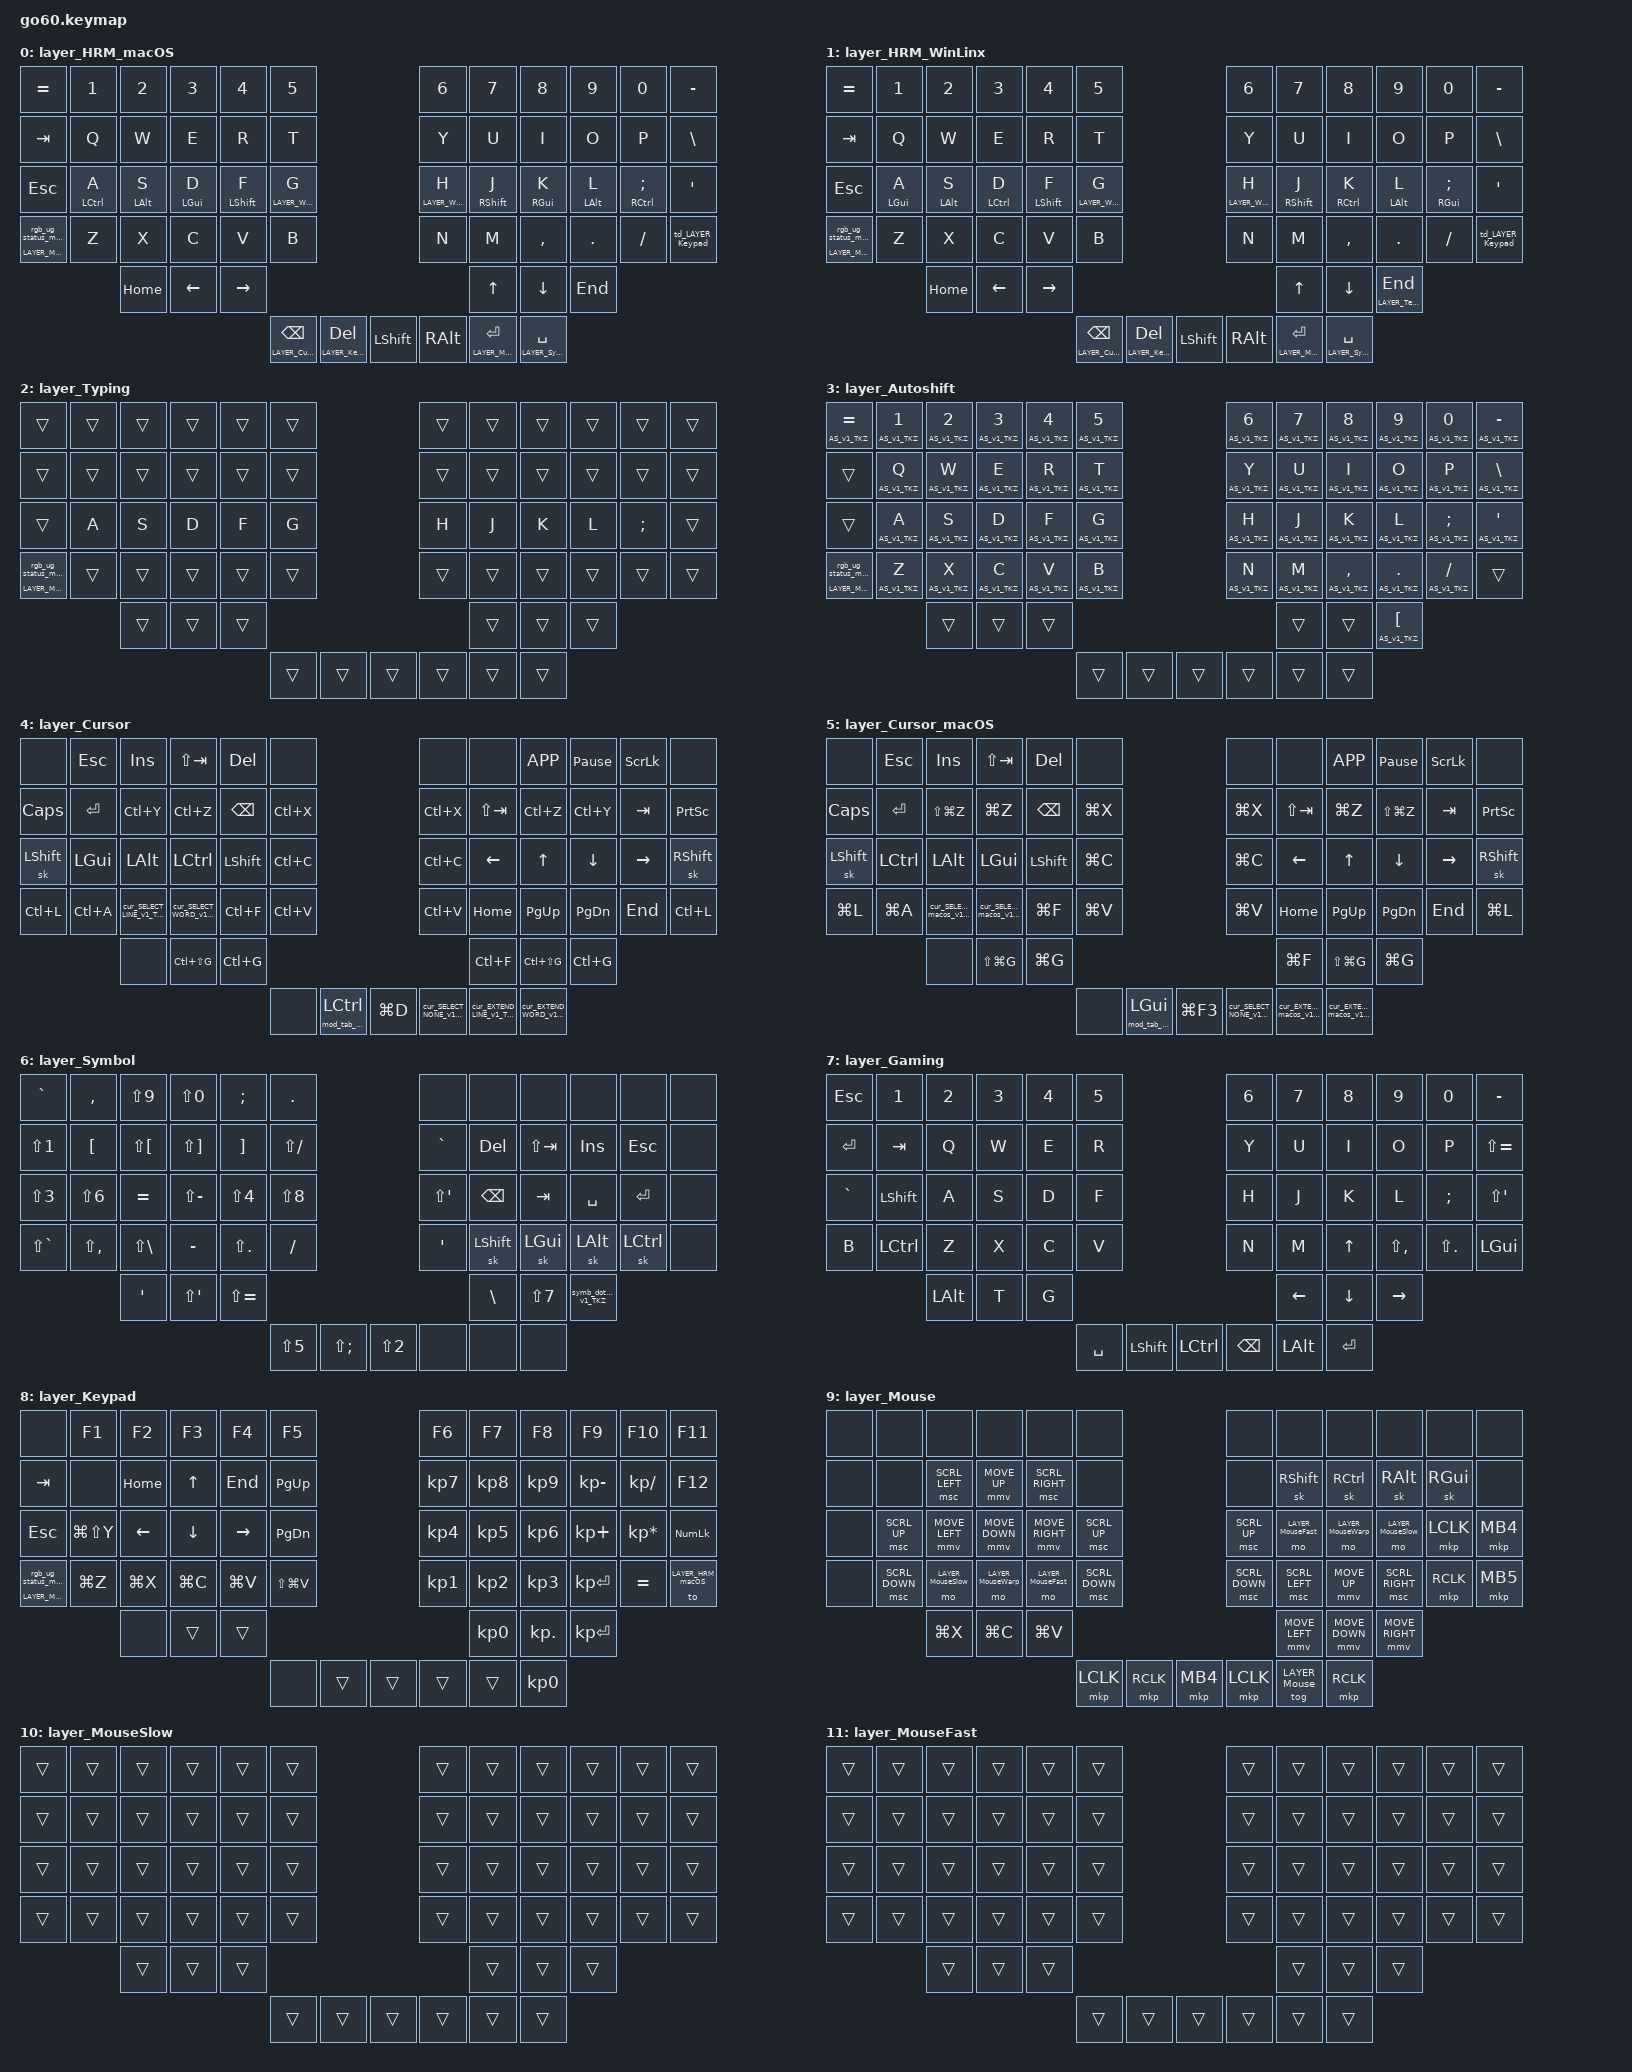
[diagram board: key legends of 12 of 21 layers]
/*
 * Copyright (c) 2020 The ZMK Contributors
 * Copyright (c) 2025 Innaworks Development Limited, trading as MoErgo
 *
 * SPDX-License-Identifier: MIT
 */


/* THIS FILE WAS GENERATED BY GO60 LAYOUT EDITOR
 *
 * This file was generated automatically. You may or may not want to
 * edit it directly.
 */

#include <behaviors.dtsi>

/* Include all behavior includes needed */

#include <dt-bindings/zmk/outputs.h>
#include <dt-bindings/zmk/keys.h>
#include <dt-bindings/zmk/bt.h>
#include <dt-bindings/zmk/rgb.h>

#include <input/processors.dtsi>
#include <dt-bindings/zmk/input_transform.h>
#include <zephyr/dt-bindings/input/input-event-codes.h>

/* On demand includes */
#include <dt-bindings/zmk/input_transform.h>
#include <dt-bindings/zmk/pointing.h>
#include <input/processors.dtsi>

/* Helper Macros, based on https://github.com/urob/zmk-helpers/ */

#pragma once

#define ZMK_HELPER_STRINGIFY(x) #x

// Preprocessor mechanism to overload macros, cf. https://stackoverflow.com/a/27051616/6114651
#define VARGS_(_10, _9, _8, _7, _6, _5, _4, _3, _2, _1, N, ...) N
#define VARGS(...) VARGS_(__VA_ARGS__, 10, 9, 8, 7, 6, 5, 4, 3, 2, 1, 0)
#define CONCAT_(a, b) a##b
#define CONCAT(a, b) CONCAT_(a, b)

#define ZMK_BEHAVIOR_CORE_tap_dance  \
    compatible = "zmk,behavior-tap-dance"; \
    #binding-cells = <0>

#define ZMK_BEHAVIOR(name, type, ...) \
    name: name { \
        ZMK_BEHAVIOR_CORE_ ## type; \
        __VA_ARGS__ \
    };

#define ZMK_TAP_DANCE(name, ...) \
    ZMK_BEHAVIOR(name, tap_dance, __VA_ARGS__)

#define ZMK_TD_LAYER(name, layer) \
    ZMK_TAP_DANCE(name, \
        tapping-term-ms = <200>; \
        bindings = <&mo layer>, <&to layer>; \
)





/* Key positions */

#define POS_LH_C6R1 0
#define POS_LH_C5R1 1
#define POS_LH_C4R1 2
#define POS_LH_C3R1 3
#define POS_LH_C2R1 4
#define POS_LH_C1R1 5
#define POS_RH_C1R1 6
#define POS_RH_C2R1 7
#define POS_RH_C3R1 8
#define POS_RH_C4R1 9
#define POS_RH_C5R1 10
#define POS_RH_C6R1 11
#define POS_LH_C6R2 12
#define POS_LH_C5R2 13
#define POS_LH_C4R2 14
#define POS_LH_C3R2 15
#define POS_LH_C2R2 16
#define POS_LH_C1R2 17
#define POS_RH_C1R2 18
#define POS_RH_C2R2 19
#define POS_RH_C3R2 20
#define POS_RH_C4R2 21
#define POS_RH_C5R2 22
#define POS_RH_C6R2 23
#define POS_LH_C6R3 24
#define POS_LH_C5R3 25
#define POS_LH_C4R3 26
#define POS_LH_C3R3 27
#define POS_LH_C2R3 28
#define POS_LH_C1R3 29
#define POS_RH_C1R3 30
#define POS_RH_C2R3 31
#define POS_RH_C3R3 32
#define POS_RH_C4R3 33
#define POS_RH_C5R3 34
#define POS_RH_C6R3 35
#define POS_LH_C6R4 36
#define POS_LH_C5R4 37
#define POS_LH_C4R4 38
#define POS_LH_C3R4 39
#define POS_LH_C2R4 40
#define POS_LH_C1R4 41
#define POS_RH_C1R4 42
#define POS_RH_C2R4 43
#define POS_RH_C3R4 44
#define POS_RH_C4R4 45
#define POS_RH_C5R4 46
#define POS_RH_C6R4 47
#define POS_LH_C4R5 48
#define POS_LH_C3R5 49
#define POS_LH_C2R5 50
#define POS_RH_C2R5 51
#define POS_RH_C3R5 52
#define POS_RH_C4R5 53
#define POS_LH_T1 54
#define POS_LH_T2 55
#define POS_LH_T3 56
#define POS_RH_T3 57
#define POS_RH_T2 58
#define POS_RH_T1 59


#define LEFT_HAND_KEYS \
  POS_LH_C1R1 POS_LH_C2R1 POS_LH_C3R1 POS_LH_C4R1 POS_LH_C5R1 POS_LH_C6R1 \
  POS_LH_C1R2 POS_LH_C2R2 POS_LH_C3R2 POS_LH_C4R2 POS_LH_C5R2 POS_LH_C6R2 \
  POS_LH_C1R3 POS_LH_C2R3 POS_LH_C3R3 POS_LH_C4R3 POS_LH_C5R3 POS_LH_C6R3 \
  POS_LH_C1R4 POS_LH_C2R4 POS_LH_C3R4 POS_LH_C4R4 POS_LH_C5R4 POS_LH_C6R4 \
              POS_LH_C2R5 POS_LH_C3R5 POS_LH_C4R5

#define RIGHT_HAND_KEYS \
  POS_RH_C1R1 POS_RH_C2R1 POS_RH_C3R1 POS_RH_C4R1 POS_RH_C5R1 POS_RH_C6R1 \
  POS_RH_C1R2 POS_RH_C2R2 POS_RH_C3R2 POS_RH_C4R2 POS_RH_C5R2 POS_RH_C6R2 \
  POS_RH_C1R3 POS_RH_C2R3 POS_RH_C3R3 POS_RH_C4R3 POS_RH_C5R3 POS_RH_C6R3 \
  POS_RH_C1R4 POS_RH_C2R4 POS_RH_C3R4 POS_RH_C4R4 POS_RH_C5R4 POS_RH_C6R4 \
              POS_RH_C2R5 POS_RH_C3R5 POS_RH_C4R5

#define THUMB_KEYS \
  POS_LH_T1 POS_LH_T2 POS_LH_T3 \
  POS_RH_T1 POS_RH_T2 POS_RH_T3

/* Environment and metadata defines */
#define KB_TYPE_GLOVE_80 1
#define KB_TYPE_GO_60    2

#define KB_TYPE          KB_TYPE_GO_60
#define EDITOR_HOST_OS   'M'

/* Automatically generated layer name defines */
#define LAYER_HRM_macOS 0
#define LAYER_HRM_WinLinx 1
#define LAYER_Typing 2
#define LAYER_Autoshift 3
#define LAYER_Cursor 4
#define LAYER_Cursor_macOS 5
#define LAYER_Symbol 6
#define LAYER_Gaming 7
#define LAYER_Keypad 8
#define LAYER_Mouse 9
#define LAYER_MouseSlow 10
#define LAYER_MouseFast 11
#define LAYER_MouseWarp 12
#define LAYER_Magic 13
#define LAYER_WM_practice 14
#define LAYER_WM_Win 15
#define LAYER_VSCode_macOS 16
#define LAYER_VSCode_Win 17
#define LAYER_Teams 18
/* Windows-only overlays; never entered by a key — see the conditional_layers node. */
#define LAYER_Keypad_Win 19
#define LAYER_Mouse_Win 20

/* To deal with the situation where there is no Lower layer, to keep &lower happy */
#ifndef LAYER_Lower
#define LAYER_Lower 0
#endif

/* Generated input processors */


/* Custom Device-tree */


/* Input Listeners */
&mmv_input_listener {
    // base pointer speed (tools/edits/mouse-speed.js)
    LAYER_Mouse {
        layers = <LAYER_Mouse>;
        input-processors = <&zip_xy_scaler 2 1>;
    };
    // LAYER_MouseSlow
    LAYER_MouseSlow {
        layers = <LAYER_MouseSlow>;
        input-processors = <&zip_xy_scaler 1 18>;
    };
    // LAYER_MouseFast
    LAYER_MouseFast {
        layers = <LAYER_MouseFast>;
        input-processors = <&zip_xy_scaler 3 2>;
    };
    // LAYER_MouseFast
    LAYER_MouseWarp {
        layers = <LAYER_MouseWarp>;
        input-processors = <&zip_xy_scaler 6 1>;
    };
};

&msc_input_listener {
    // base scroll rate (tools/edits/mouse-speed.js)
    LAYER_Mouse {
        layers = <LAYER_Mouse>;
        input-processors = <&zip_scroll_scaler 1 3>;
    };
    // LAYER_MouseSlow
    LAYER_MouseSlow {
        layers = <LAYER_MouseSlow>;
        input-processors = <&zip_scroll_scaler 1 9>;
    };
    // LAYER_MouseFast
    LAYER_MouseFast {
        layers = <LAYER_MouseFast>;
        input-processors = <&zip_scroll_scaler 3 1>;
    };
    // LAYER_MouseWarp
    LAYER_MouseWarp {
        layers = <LAYER_MouseWarp>;
        input-processors = <&zip_scroll_scaler 12 1>;
    };
};

&cirque_lh_listener {
    // Left pad = scroll wheel. Gains are ABSOLUTE: a speed hold's override
    // replaces these base processors rather than stacking on them (ZMK
    // input-listener semantics, no `process-next`), so each tier is spelled
    // out in full. Base is MoErgo's stock 1/8; raw deltas (the old base) were
    // 8x that and unusable. Same direction on every tier.
    input-processors = <&zip_xy_scaler 1 8>, <&zip_xy_to_scroll_mapper>, <&zip_temp_layer LAYER_Mouse 250>;
    layer_MouseSlow {
        layers = <LAYER_MouseSlow>;
        input-processors = <&zip_xy_scaler 1 16>, <&zip_xy_to_scroll_mapper>;
    };
    layer_MouseFast {
        layers = <LAYER_MouseFast>;
        input-processors = <&zip_xy_scaler 1 4>, <&zip_xy_to_scroll_mapper>;
    };
    layer_MouseWarp {
        layers = <LAYER_MouseWarp>;
        input-processors = <&zip_xy_scaler 1 2>, <&zip_xy_to_scroll_mapper>;
    };
};

&cirque_rh_listener {
    // Right pad = pointer. Absolute gains, same replace-not-stack rule as the
    // left pad. Base is MoErgo's stock 3x (raw 1x was unusably slow); Warp is
    // stock's own fast tier, Slow keeps raw 1x for pixel work.
    input-processors = <&zip_xy_scaler 3 1>, <&zip_temp_layer LAYER_Mouse 250>;
    layer_MouseSlow {
        layers = <LAYER_MouseSlow>;
        input-processors = <&zip_xy_scaler 1 1>;
    };
    layer_MouseFast {
        layers = <LAYER_MouseFast>;
        input-processors = <&zip_xy_scaler 6 1>;
    };
    layer_MouseWarp {
        layers = <LAYER_MouseWarp>;
        input-processors = <&zip_xy_scaler 9 1>;
    };
};

/* System behavior and macros */
/ {
    behaviors {
        ZMK_TD_LAYER(lower, LAYER_Lower)
    };
};

/ {
    macros {
        rgb_ug_status_macro: rgb_ug_status_macro {
            label = "RGB_UG_STATUS";
            compatible = "zmk,behavior-macro";
            #binding-cells = <0>;
            bindings
                = <&rgb_ug RGB_STATUS>;
        };
    };
};

/ {
#ifdef BT_DISC_CMD
    behaviors {
        bt_0: bt_0 {
            compatible = "zmk,behavior-tap-dance";
            label = "BT_0";
            #binding-cells = <0>;
            tapping-term-ms = <200>;
            bindings = <&bt_select_0>, <&bt BT_DISC 0>;
        };
        bt_1: bt_1 {
            compatible = "zmk,behavior-tap-dance";
            label = "BT_1";
            #binding-cells = <0>;
            tapping-term-ms = <200>;
            bindings = <&bt_select_1>, <&bt BT_DISC 1>;
        };
        bt_2: bt_2 {
            compatible = "zmk,behavior-tap-dance";
            label = "BT_2";
            #binding-cells = <0>;
            tapping-term-ms = <200>;
            bindings = <&bt_select_2>, <&bt BT_DISC 2>;
        };
        bt_3: bt_3 {
            compatible = "zmk,behavior-tap-dance";
            label = "BT_3";
            #binding-cells = <0>;
            tapping-term-ms = <200>;
            bindings = <&bt_select_3>, <&bt BT_DISC 3>;
        };
    };
    macros {
        bt_select_0: bt_select_0 {
            label = "BT_SELECT_0";
            compatible = "zmk,behavior-macro";
            #binding-cells = <0>;
            bindings
                = <&out OUT_BLE>,
                  <&bt BT_SEL 0>;
        };
        bt_select_1: bt_select_1 {
            label = "BT_SELECT_1";
            compatible = "zmk,behavior-macro";
            #binding-cells = <0>;
            bindings
                = <&out OUT_BLE>,
                  <&bt BT_SEL 1>;
        };
        bt_select_2: bt_select_2 {
            label = "BT_SELECT_2";
            compatible = "zmk,behavior-macro";
            #binding-cells = <0>;
            bindings
                = <&out OUT_BLE>,
                  <&bt BT_SEL 2>;
        };
        bt_select_3: bt_select_3 {
            label = "BT_SELECT_3";
            compatible = "zmk,behavior-macro";
            #binding-cells = <0>;
            bindings
                = <&out OUT_BLE>,
                  <&bt BT_SEL 3>;
        };
    };
#else
    macros {
        bt_0: bt_0 {
            label = "BT_0";
            compatible = "zmk,behavior-macro";
            #binding-cells = <0>;
            bindings
                = <&out OUT_BLE>,
                  <&bt BT_SEL 0>;
        };
        bt_1: bt_1 {
            label = "BT_1";
            compatible = "zmk,behavior-macro";
            #binding-cells = <0>;
            bindings
                = <&out OUT_BLE>,
                  <&bt BT_SEL 1>;
        };
        bt_2: bt_2 {
            label = "BT_2";
            compatible = "zmk,behavior-macro";
            #binding-cells = <0>;
            bindings
                = <&out OUT_BLE>,
                  <&bt BT_SEL 2>;
        };
        bt_3: bt_3 {
            label = "BT_3";
            compatible = "zmk,behavior-macro";
            #binding-cells = <0>;
            bindings
                = <&out OUT_BLE>,
                  <&bt BT_SEL 3>;
        };
    };
#endif
};

/ {
    behaviors {
        magic: magic {
            compatible = "zmk,behavior-hold-tap";
            label = "MAGIC_HOLD_TAP";
            #binding-cells = <2>;
            flavor = "tap-preferred";
            tapping-term-ms = <200>;
            bindings = <&mo>, <&rgb_ug_status_macro>;
        };
    };
};


/* Custom Defined Behaviors */
/ {

};

/* Automatically generated macro definitions */
/ {
    macros {

        // AutoShift Helper- &AS main macro is chained to &AS_HT hold tap and &AS_Shifted macro - TailorKey
        AS_Shifted_v1_TKZ: AS_Shifted_v1_TKZ {
            label = "&AS_SHIFTED_V1_TKZ";
            compatible = "zmk,behavior-macro-one-param";
            #binding-cells = <1>;
            tap-ms = <0>;
            wait-ms = <0>;
            bindings = <&macro_press>
                , <&kp LSHFT>
                , <&macro_tap>
                , <&macro_param_1to1>
                , <&kp MACRO_PLACEHOLDER>
                , <&macro_release>
                , <&kp LSHFT>;
        };

        // AutoShift (Assign &AS to a Key) - &AS main macro is chained to &AS_HT hold tap and &AS_Shifted macro - TailorKey
        AS_v1_TKZ: AS_v1_TKZ {
            label = "&AS_V1_TKZ";
            compatible = "zmk,behavior-macro-one-param";
            #binding-cells = <1>;
            tap-ms = <0>;
            wait-ms = <0>;
            bindings = <&macro_press>
                , <&macro_param_1to1>
                , <&macro_param_1to2>
                , <&AS_HT_v2_TKZ MACRO_PLACEHOLDER MACRO_PLACEHOLDER>
                , <&macro_pause_for_release>
                , <&macro_release>
                , <&macro_param_1to1>
                , <&macro_param_1to2>
                , <&AS_HT_v2_TKZ MACRO_PLACEHOLDER MACRO_PLACEHOLDER>;
        };

        // Cursor Layer - Extent Line (seq) - TailorKey
        cur_EXTEND_LINE_macos_v1_TKZ: cur_EXTEND_LINE_macos_v1_TKZ {
            label = "&CUR_EXTEND_LINE_MACOS_V1_TKZ";
            compatible = "zmk,behavior-macro";
            #binding-cells = <0>;
            tap-ms = <1>;
            wait-ms = <1>;
            bindings = <&kp LG(LS(RIGHT))>;
        };

        // Cursor Layer - Extent Line (seq) - TailorKey
        cur_EXTEND_LINE_v1_TKZ: cur_EXTEND_LINE_v1_TKZ {
            label = "&CUR_EXTEND_LINE_V1_TKZ";
            compatible = "zmk,behavior-macro";
            #binding-cells = <0>;
            tap-ms = <1>;
            wait-ms = <1>;
            bindings = <&kp LS(END)>;
        };

        // Cursor Layer - Extend Word (seq) - TailorKey
        cur_EXTEND_WORD_macos_v1_TKZ: cur_EXTEND_WORD_macos_v1_TKZ {
            label = "&CUR_EXTEND_WORD_MACOS_V1_TKZ";
            compatible = "zmk,behavior-macro";
            #binding-cells = <0>;
            tap-ms = <1>;
            wait-ms = <1>;
            bindings = <&kp LA(LS(RIGHT))>;
        };

        // Cursor Layer - Extend Word (seq) - TailorKey
        cur_EXTEND_WORD_v1_TKZ: cur_EXTEND_WORD_v1_TKZ {
            label = "&CUR_EXTEND_WORD_V1_TKZ";
            compatible = "zmk,behavior-macro";
            #binding-cells = <0>;
            tap-ms = <1>;
            wait-ms = <1>;
            bindings = <&kp LC(LS(RIGHT))>;
        };

        // Cursor Layer macos - Select Line (seq) - TailorKey
        cur_SELECT_LINE_macos_v1_TKZ: cur_SELECT_LINE_macos_v1_TKZ {
            label = "&CUR_SELECT_LINE_MACOS_V1_TKZ";
            compatible = "zmk,behavior-macro";
            #binding-cells = <0>;
            tap-ms = <1>;
            wait-ms = <1>;
            bindings = <&kp LG(LEFT)>
                , <&kp LG(LS(RIGHT))>;
        };

        // Cursor Layer - Select Line (seq) - TailorKey
        cur_SELECT_LINE_v1_TKZ: cur_SELECT_LINE_v1_TKZ {
            label = "&CUR_SELECT_LINE_V1_TKZ";
            compatible = "zmk,behavior-macro";
            #binding-cells = <0>;
            tap-ms = <1>;
            wait-ms = <1>;
            bindings = <&kp HOME>
                , <&kp LS(END)>;
        };

        // Cursor Layer - Select None (seq) - TailorKey
        cur_SELECT_NONE_v1_TKZ: cur_SELECT_NONE_v1_TKZ {
            label = "&CUR_SELECT_NONE_V1_TKZ";
            compatible = "zmk,behavior-macro";
            #binding-cells = <0>;
            tap-ms = <1>;
            wait-ms = <1>;
            bindings = <&kp DOWN>
                , <&kp UP>
                , <&kp RIGHT>
                , <&kp LEFT>;
        };

        // Cursor Layer - Select Word (seq) - TailorKey
        cur_SELECT_WORD_macos_v1_TKZ: cur_SELECT_WORD_macos_v1_TKZ {
            label = "&CUR_SELECT_WORD_MACOS_V1_TKZ";
            compatible = "zmk,behavior-macro";
            #binding-cells = <0>;
            tap-ms = <1>;
            wait-ms = <1>;
            bindings = <&kp LA(LEFT)>
                , <&kp LA(LS(RIGHT))>;
        };

        // Cursor Layer - Select Word (seq) - TailorKey
        cur_SELECT_WORD_v1_TKZ: cur_SELECT_WORD_v1_TKZ {
            label = "&CUR_SELECT_WORD_V1_TKZ";
            compatible = "zmk,behavior-macro";
            #binding-cells = <0>;
            tap-ms = <1>;
            wait-ms = <1>;
            bindings = <&kp LC(LEFT)>
                , <&kp LC(LS(RIGHT))>;
        };

        // mod_tab_switcher_chord -  TailorKey
        mod_tab_chord_v2_TKZ: mod_tab_chord_v2_TKZ {
            label = "&MOD_TAB_CHORD_V2_TKZ";
            compatible = "zmk,behavior-macro-two-param";
            #binding-cells = <2>;
            tap-ms = <0>;
            wait-ms = <0>;
            bindings = <&macro_press>
                , <&macro_param_2to1>
                , <&mo MACRO_PLACEHOLDER>
                , <&macro_press>
                , <&macro_param_1to1>
                , <&mod_tab_v2_TKZ MACRO_PLACEHOLDER>
                , <&macro_pause_for_release>
                , <&macro_release>
                , <&macro_param_1to1>
                , <&mod_tab_v2_TKZ MACRO_PLACEHOLDER>
                , <&macro_release>
                , <&macro_param_2to1>
                , <&mo MACRO_PLACEHOLDER>;
        };

        // mod_tab_switcher - TailorKey
        //
        //
        mod_tab_v2_TKZ: mod_tab_v2_TKZ {
            label = "&MOD_TAB_V2_TKZ";
            compatible = "zmk,behavior-macro-one-param";
            #binding-cells = <1>;
            tap-ms = <0>;
            wait-ms = <0>;
            bindings = <&macro_press>
                , <&macro_param_1to1>
                , <&kp MACRO_PLACEHOLDER>
                , <&macro_tap>
                , <&kp TAB>
                , <&macro_pause_for_release>
                , <&macro_release>
                , <&macro_param_1to1>
                , <&kp MACRO_PLACEHOLDER>;
        };

        // macro string1 sample - Magic Layer F1 - Text output sample macro 1 "¡Hola!" - TailorKey
        mstr1_v1_TKZ: mstr1_v1_TKZ {
            label = "&MSTR1_V1_TKZ";
            compatible = "zmk,behavior-macro";
            #binding-cells = <0>;
            bindings = <&macro_press>
                , <&kp RALT>
                , <&macro_tap>
                , <&kp KP_N0>
                , <&kp KP_N1>
                , <&kp KP_N6>
                , <&kp KP_N1>
                , <&macro_release>
                , <&kp RALT>
                , <&macro_press>
                , <&kp LSHFT>
                , <&macro_tap>
                , <&kp H>
                , <&macro_release>
                , <&kp LSHFT>
                , <&macro_tap>
                , <&kp O>
                , <&kp L>
                , <&kp A>
                , <&kp LS(N1)>
                , <&kp SPACE>
                , <&kp RET>;
        };

        // Symbol layer dot dot
        symb_dotdot_v1_TKZ: symb_dotdot_v1_TKZ {
            label = "&SYMB_DOTDOT_V1_TKZ";
            compatible = "zmk,behavior-macro";
            #binding-cells = <0>;
            tap-ms = <0>;
            wait-ms = <0>;
            bindings = <&macro_tap>
                , <&kp DOT>
                , <&kp DOT>;
        };

        // BT profile 0 = the Mac. Taps Ctrl+Shift+F17 so the machine being left pushes the MX Master to the same host, hops, then lands the base layer on macOS
        bt_hop_0: bt_hop_0 {
            label = "&BT_HOP_0";
            compatible = "zmk,behavior-macro";
            #binding-cells = <0>;
            tap-ms = <30>;
            wait-ms = <125>;
            bindings = <&kp LC(LS(F17))>
                , <&out OUT_BLE>
                , <&bt BT_SEL 0>
                , <&to LAYER_HRM_macOS>;
        };

        // BT profile 1 = the work laptop. Taps Ctrl+Shift+F18 so the machine being left pushes the MX Master to the same host, hops, then lands the base layer on Windows
        bt_hop_1: bt_hop_1 {
            label = "&BT_HOP_1";
            compatible = "zmk,behavior-macro";
            #binding-cells = <0>;
            tap-ms = <30>;
            wait-ms = <125>;
            bindings = <&kp LC(LS(F18))>
                , <&out OUT_BLE>
                , <&bt BT_SEL 1>
                , <&to LAYER_HRM_WinLinx>;
        };

        // BT profile 2 = the personal Windows desktop. Taps Ctrl+Shift+F19 so the machine being left pushes the MX Master to the same host, hops, then lands the base layer on Windows
        bt_hop_2: bt_hop_2 {
            label = "&BT_HOP_2";
            compatible = "zmk,behavior-macro";
            #binding-cells = <0>;
            tap-ms = <30>;
            wait-ms = <125>;
            bindings = <&kp LC(LS(F19))>
                , <&out OUT_BLE>
                , <&bt BT_SEL 2>
                , <&to LAYER_HRM_WinLinx>;
        };

        // BT profile 3 — spare. No machine claims Ctrl+Shift+F20 and no base layer follows it; the hop is all this one does
        bt_hop_3: bt_hop_3 {
            label = "&BT_HOP_3";
            compatible = "zmk,behavior-macro";
            #binding-cells = <0>;
            tap-ms = <30>;
            wait-ms = <125>;
            bindings = <&kp LC(LS(F20))>
                , <&out OUT_BLE>
                , <&bt BT_SEL 3>;
        };
    };
};

/* Automatically generated behavior definitions */
/ {
    behaviors {

        // Layer tap dance behaviors

        ZMK_TD_LAYER(td_LAYER_Keypad, 8)

        // AutoShift Helper - &AS main macro is chained to &AS_HT hold tap and &AS_Shifted macro. For faster typists, it is recommended to decrease the tapping-term-ms value. A suggested value is 135 ms.
        // More: https://github.com/nickcoutsos/keymap-editor/wiki/Autoshift-using-ZMK-behaviors
        AS_HT_v2_TKZ: AS_HT_v2_TKZ {
            compatible = "zmk,behavior-hold-tap";
            #binding-cells = <2>;
            tapping-term-ms = <190>;
            bindings = <&AS_Shifted_v1_TKZ>, <&kp>;
            flavor = "tap-preferred";
        };

        // Homerow Mod for the left index finger - TailorKey.
        // For advanced tuning of HRM values, see: https://docs.google.com/spreadsheets/d/1ESgObQelyz4lnKlfwLYsmofLJulOMK5RdGBsopLe2o8
        HRM_left_index_v1_TKZ: HRM_left_index_v1_TKZ {
            compatible = "zmk,behavior-hold-tap";
            #binding-cells = <2>;
            tapping-term-ms = <190>;
            bindings = <&kp>, <&kp>;
            flavor = "tap-preferred";
            quick-tap-ms = <300>;
            require-prior-idle-ms = <150>;
            hold-trigger-key-positions = <POS_RH_T3 POS_RH_T2 POS_RH_T1 POS_RH_C1R1 POS_RH_C2R1 POS_RH_C3R1 POS_RH_C4R1 POS_RH_C5R1 POS_RH_C1R2 POS_RH_C2R2 POS_RH_C3R2 POS_RH_C4R2 POS_RH_C5R2 POS_RH_C1R3 POS_RH_C2R3 POS_RH_C3R3 POS_RH_C4R3 POS_RH_C5R3 POS_RH_C1R4 POS_RH_C2R4 POS_RH_C3R4 POS_RH_C4R4 POS_RH_C5R4 POS_RH_C2R5 POS_RH_C3R5 POS_RH_C4R5 POS_RH_C6R1 POS_RH_C6R2 POS_RH_C6R3 POS_RH_C6R4 POS_LH_T2 POS_LH_T3 POS_LH_T1>;
            hold-trigger-on-release;
        };

        // Homerow Mod for the left middle finger - TailorKey
        HRM_left_middy_v1_TKZ: HRM_left_middy_v1_TKZ {
            compatible = "zmk,behavior-hold-tap";
            #binding-cells = <2>;
            tapping-term-ms = <210>;
            bindings = <&kp>, <&kp>;
            flavor = "tap-preferred";
            quick-tap-ms = <300>;
            require-prior-idle-ms = <150>;
            hold-trigger-key-positions = <POS_RH_T3 POS_RH_T2 POS_RH_T1 POS_RH_C1R1 POS_RH_C2R1 POS_RH_C3R1 POS_RH_C4R1 POS_RH_C5R1 POS_RH_C1R2 POS_RH_C2R2 POS_RH_C3R2 POS_RH_C4R2 POS_RH_C5R2 POS_RH_C1R3 POS_RH_C2R3 POS_RH_C3R3 POS_RH_C4R3 POS_RH_C5R3 POS_RH_C1R4 POS_RH_C2R4 POS_RH_C3R4 POS_RH_C4R4 POS_RH_C5R4 POS_RH_C2R5 POS_RH_C3R5 POS_RH_C4R5 POS_RH_C6R1 POS_RH_C6R2 POS_RH_C6R3 POS_RH_C6R4 POS_LH_T1 POS_LH_T2 POS_LH_T3>;
            hold-trigger-on-release;
        };

        // Homerow Mod for the left pinky - TailorKey
        HRM_left_pinky_v1_TKZ: HRM_left_pinky_v1_TKZ {
            compatible = "zmk,behavior-hold-tap";
            #binding-cells = <2>;
            tapping-term-ms = <280>;
            bindings = <&kp>, <&kp>;
            flavor = "tap-preferred";
            quick-tap-ms = <300>;
            require-prior-idle-ms = <150>;
            hold-trigger-key-positions = <POS_RH_T3 POS_RH_T2 POS_RH_T1 POS_RH_C1R1 POS_RH_C2R1 POS_RH_C3R1 POS_RH_C4R1 POS_RH_C5R1 POS_RH_C6R1 POS_RH_C2R2 POS_RH_C3R2 POS_RH_C4R2 POS_RH_C5R2 POS_RH_C6R2 POS_RH_C3R3 POS_RH_C4R3 POS_RH_C5R3 POS_RH_C6R3 POS_RH_C3R4 POS_RH_C4R4 POS_RH_C5R4 POS_RH_C6R4 POS_RH_C1R2 POS_RH_C1R3 POS_RH_C2R3 POS_RH_C1R4 POS_RH_C2R4 POS_RH_C2R5 POS_RH_C3R5 POS_RH_C4R5 POS_LH_T1 POS_LH_T2 POS_LH_T3>;
            hold-trigger-on-release;
        };

        // Homerow Mod for the left ring finger 1 - TailorKey
        HRM_left_ring_v1_TKZ: HRM_left_ring_v1_TKZ {
            compatible = "zmk,behavior-hold-tap";
            #binding-cells = <2>;
            tapping-term-ms = <240>;
            bindings = <&kp>, <&kp>;
            flavor = "tap-preferred";
            quick-tap-ms = <300>;
            require-prior-idle-ms = <150>;
            hold-trigger-key-positions = <POS_RH_T3 POS_RH_T2 POS_RH_T1 POS_RH_C1R1 POS_RH_C2R1 POS_RH_C3R1 POS_RH_C4R1 POS_RH_C5R1 POS_RH_C1R2 POS_RH_C2R2 POS_RH_C3R2 POS_RH_C4R2 POS_RH_C5R2 POS_RH_C1R3 POS_RH_C2R3 POS_RH_C3R3 POS_RH_C4R3 POS_RH_C5R3 POS_RH_C1R4 POS_RH_C2R4 POS_RH_C3R4 POS_RH_C4R4 POS_RH_C5R4 POS_RH_C2R5 POS_RH_C3R5 POS_RH_C4R5 POS_RH_C6R1 POS_RH_C6R2 POS_RH_C6R3 POS_RH_C6R4 POS_LH_T1 POS_LH_T2 POS_LH_T3>;
            hold-trigger-on-release;
        };

        // Homerow Mod for the right index finger - TailorKey
        HRM_right_index_v1_TKZ: HRM_right_index_v1_TKZ {
            compatible = "zmk,behavior-hold-tap";
            #binding-cells = <2>;
            tapping-term-ms = <190>;
            bindings = <&kp>, <&kp>;
            flavor = "tap-preferred";
            quick-tap-ms = <300>;
            require-prior-idle-ms = <150>;
            hold-trigger-key-positions = <POS_LH_T3 POS_LH_T2 POS_LH_T1 POS_LH_C6R1 POS_LH_C5R1 POS_LH_C4R1 POS_LH_C3R1 POS_LH_C2R1 POS_LH_C6R2 POS_LH_C5R2 POS_LH_C4R2 POS_LH_C3R2 POS_LH_C2R2 POS_LH_C1R2 POS_LH_C6R3 POS_LH_C5R3 POS_LH_C4R3 POS_LH_C3R3 POS_LH_C2R3 POS_LH_C1R3 POS_LH_C6R4 POS_LH_C5R4 POS_LH_C4R4 POS_LH_C3R4 POS_LH_C2R4 POS_LH_C1R4 POS_LH_C4R5 POS_LH_C3R5 POS_LH_C2R5 POS_LH_C1R1 POS_RH_T3 POS_RH_T2 POS_RH_T1>;
            hold-trigger-on-release;
        };

        // Homerow Mod for the right middle finger - TailorKey
        HRM_right_middy_v1_TKZ: HRM_right_middy_v1_TKZ {
            compatible = "zmk,behavior-hold-tap";
            #binding-cells = <2>;
            tapping-term-ms = <210>;
            bindings = <&kp>, <&kp>;
            flavor = "tap-preferred";
            quick-tap-ms = <300>;
            require-prior-idle-ms = <150>;
            hold-trigger-key-positions = <POS_LH_T3 POS_LH_T2 POS_LH_T1 POS_LH_C6R1 POS_LH_C5R1 POS_LH_C4R1 POS_LH_C3R1 POS_LH_C2R1 POS_LH_C6R2 POS_LH_C5R2 POS_LH_C4R2 POS_LH_C3R2 POS_LH_C2R2 POS_LH_C1R2 POS_LH_C6R3 POS_LH_C5R3 POS_LH_C4R3 POS_LH_C3R3 POS_LH_C2R3 POS_LH_C1R3 POS_LH_C6R4 POS_LH_C5R4 POS_LH_C4R4 POS_LH_C3R4 POS_LH_C2R4 POS_LH_C1R4 POS_LH_C4R5 POS_LH_C3R5 POS_LH_C2R5 POS_LH_C1R1 POS_RH_T3 POS_RH_T2 POS_RH_T1>;
            hold-trigger-on-release;
        };

        // Homerow Mod for the right pinky - TailorKey
        HRM_right_pinky_v1_TKZ: HRM_right_pinky_v1_TKZ {
            compatible = "zmk,behavior-hold-tap";
            #binding-cells = <2>;
            tapping-term-ms = <280>;
            bindings = <&kp>, <&kp>;
            flavor = "tap-preferred";
            quick-tap-ms = <300>;
            require-prior-idle-ms = <150>;
            hold-trigger-key-positions = <POS_LH_T3 POS_LH_T2 POS_LH_T1 POS_LH_C6R1 POS_LH_C5R1 POS_LH_C4R1 POS_LH_C3R1 POS_LH_C2R1 POS_LH_C6R2 POS_LH_C5R2 POS_LH_C4R2 POS_LH_C3R2 POS_LH_C2R2 POS_LH_C1R2 POS_LH_C6R3 POS_LH_C5R3 POS_LH_C4R3 POS_LH_C3R3 POS_LH_C2R3 POS_LH_C1R3 POS_LH_C6R4 POS_LH_C5R4 POS_LH_C4R4 POS_LH_C3R4 POS_LH_C2R4 POS_LH_C1R4 POS_LH_C4R5 POS_LH_C3R5 POS_LH_C2R5 POS_LH_C1R1 POS_RH_T3 POS_RH_T2 POS_RH_T1>;
            hold-trigger-on-release;
        };

        // Homerow Mod for the right ring 1 - TailorKey
        //
        HRM_right_ring_v1_TKZ: HRM_right_ring_v1_TKZ {
            compatible = "zmk,behavior-hold-tap";
            #binding-cells = <2>;
            tapping-term-ms = <240>;
            bindings = <&kp>, <&kp>;
            flavor = "tap-preferred";
            quick-tap-ms = <300>;
            require-prior-idle-ms = <150>;
            hold-trigger-key-positions = <POS_LH_T3 POS_LH_T2 POS_LH_T1 POS_LH_C6R1 POS_LH_C5R1 POS_LH_C4R1 POS_LH_C3R1 POS_LH_C2R1 POS_LH_C6R2 POS_LH_C5R2 POS_LH_C4R2 POS_LH_C3R2 POS_LH_C2R2 POS_LH_C1R2 POS_LH_C6R3 POS_LH_C5R3 POS_LH_C4R3 POS_LH_C3R3 POS_LH_C2R3 POS_LH_C1R3 POS_LH_C6R4 POS_LH_C5R4 POS_LH_C4R4 POS_LH_C3R4 POS_LH_C2R4 POS_LH_C1R4 POS_LH_C4R5 POS_LH_C3R5 POS_LH_C2R5 POS_LH_C1R1 POS_RH_T3 POS_RH_T2 POS_RH_T1>;
            hold-trigger-on-release;
        };

        // space_layer_access - TailorKey
        space_v3_TKZ: space_v3_TKZ {
            compatible = "zmk,behavior-hold-tap";
            #binding-cells = <2>;
            tapping-term-ms = <250>;
            bindings = <&mo>, <&kp>;
            flavor = "tap-preferred";
            quick-tap-ms = <150>;
            require-prior-idle-ms = <200>;
        };

        // thumb_layer_access - TailorKey
        thumb_v2_TKZ: thumb_v2_TKZ {
            compatible = "zmk,behavior-hold-tap";
            #binding-cells = <2>;
            tapping-term-ms = <250>;
            bindings = <&mo>, <&kp>;
            flavor = "tap-preferred";
            quick-tap-ms = <300>;
            require-prior-idle-ms = <150>;
        };

        // WM practice layer entry on G. Positional: only the WM keys can trigger the hold, so ordinary words containing g resolve as a tap.
        WM_hold_v1: WM_hold_v1 {
            compatible = "zmk,behavior-hold-tap";
            #binding-cells = <2>;
            tapping-term-ms = <250>;
            bindings = <&mo>, <&kp>;
            flavor = "tap-preferred";
            quick-tap-ms = <300>;
            require-prior-idle-ms = <150>;
            hold-trigger-key-positions = <POS_RH_C2R2 POS_RH_C3R2 POS_RH_C4R2 POS_RH_C5R2 POS_RH_C2R3 POS_RH_C3R3 POS_RH_C4R3 POS_RH_C5R3 POS_RH_C2R4 POS_RH_C3R4 POS_RH_C4R4 POS_RH_C5R4 POS_LH_T3 POS_LH_C6R1>;
        };

        // WM practice layer entry on H, mirroring the G entry. Positional: only the LEFT-hand WM keys can trigger the hold. Higher idle guard than G because H is followed by a trigger key in "have"/"he"/"has", which G is not.
        WM_hold_H_v1: WM_hold_H_v1 {
            compatible = "zmk,behavior-hold-tap";
            #binding-cells = <2>;
            tapping-term-ms = <250>;
            bindings = <&mo>, <&kp>;
            flavor = "tap-preferred";
            quick-tap-ms = <300>;
            require-prior-idle-ms = <250>;
            hold-trigger-key-positions = <POS_LH_C6R1 POS_LH_C5R2 POS_LH_C4R2 POS_LH_C3R2 POS_LH_C2R2 POS_LH_C5R3 POS_LH_C4R3 POS_LH_C3R3 POS_LH_C2R3 POS_LH_C5R4 POS_LH_C4R4 POS_LH_C3R4 POS_LH_C2R4 POS_LH_T3>;
        };

    };
};

/*
 * Windows overlays for the two layers TailorKey only ever built for macOS.
 *
 * Keypad and Mouse are single layers that BOTH bases reach, and their
 * clipboard keys are hardcoded `LG(...)` — Cmd on macOS, the Windows key
 * on Windows, where Win+X/V/C/Z open the Quick Link menu, clipboard
 * history, Copilot and Snap Layouts instead of editing anything. Present
 * since the original TailorKey export; TailorKey ships an OS twin for
 * Cursor only.
 *
 * These fire automatically whenever the Windows base is the active base
 * AND Keypad/Mouse is up, and are `&trans` at every other position, so
 * they cost 9 real bindings rather than two duplicated 60-key layers.
 *
 * Conditional layers rather than twin layers specifically because of the
 * Mouse case: `&cirque_{lh,rh}_listener` hardcode
 * `zip_temp_layer LAYER_Mouse`, so pointer motion raises layer 9 no matter
 * which base is active. A twin selected from the Windows thumb key would
 * fix the thumb path and leave the trackpad path still sending Cmd. A
 * conditional layer watches layer STATE, so it covers both ways in.
 *
 * Both then-layers must outrank every if-layer, which is why they sit at
 * 19/20 at the end of the keymap.
 */
/ {
    conditional_layers {
        compatible = "zmk,conditional-layers";

        keypad_win {
            if-layers = <LAYER_HRM_WinLinx LAYER_Keypad>;
            then-layer = <LAYER_Keypad_Win>;
        };

        mouse_win {
            if-layers = <LAYER_HRM_WinLinx LAYER_Mouse>;
            then-layer = <LAYER_Mouse_Win>;
        };
    };
};

/* Automatically generated combos definitions */
/ {
    combos {
        compatible = "zmk,combos";

        // capslock when pressing both T1's - TailorKey
        combo_capslock_v1_TKZ {
            timeout-ms = <50>;
            key-positions = <POS_LH_T1 POS_RH_T1>;
            bindings = <&kp CAPS>;
            layers = <LAYER_HRM_macOS LAYER_HRM_WinLinx LAYER_Autoshift>;
        };

        // F4 combo for Go60 - TailorKey
        combo_F4_cb_v1_TKZ {
            key-positions = <POS_LH_C2R2 POS_LH_C2R1>;
            bindings = <&kp F4>;
            layers = <LAYER_HRM_macOS LAYER_HRM_WinLinx LAYER_Typing LAYER_Autoshift>;
        };

        // F1 combo for Go60 - TailorKey
        combo_F1_cb_v1_TKZ {
            key-positions = <POS_LH_C5R1 POS_LH_C5R2>;
            bindings = <&kp F1>;
            layers = <LAYER_HRM_macOS LAYER_HRM_WinLinx LAYER_Typing LAYER_Autoshift>;
        };

        // F10 combo for Go60 - TailorKey
        combo_F10_cb_v1_TKZ {
            key-positions = <POS_RH_C5R1 POS_RH_C5R2>;
            bindings = <&kp F10>;
            layers = <LAYER_HRM_macOS LAYER_HRM_WinLinx LAYER_Typing LAYER_Autoshift>;
        };

        // F11 combo for Go60 - TailorKey
        combo_F11_cb_v1_TKZ {
            key-positions = <POS_RH_C6R1 POS_RH_C6R2>;
            bindings = <&kp F11>;
            layers = <LAYER_HRM_macOS LAYER_HRM_WinLinx LAYER_Typing LAYER_Autoshift>;
        };

        // F12 combo for Go60 - TailorKey
        combo_F12_cb_v1_TKZ {
            key-positions = <POS_RH_C5R1 POS_RH_C6R1>;
            bindings = <&kp F12>;
            layers = <LAYER_HRM_macOS LAYER_HRM_WinLinx LAYER_Typing LAYER_Autoshift>;
        };

        // F2 combo for Go60 - TailorKey
        combo_F2_cb_v1_TKZ {
            key-positions = <POS_LH_C4R2 POS_LH_C4R1>;
            bindings = <&kp F2>;
            layers = <LAYER_HRM_macOS LAYER_HRM_WinLinx LAYER_Typing LAYER_Autoshift>;
        };

        // F3 combo for Go60 - TailorKey
        combo_F3_cb_v1_TKZ {
            key-positions = <POS_LH_C3R2 POS_LH_C3R1>;
            bindings = <&kp F3>;
            layers = <LAYER_HRM_macOS LAYER_HRM_WinLinx LAYER_Typing LAYER_Autoshift>;
        };

        // F5 combo for Go60 - TailorKey
        combo_F5_cb_v1_TKZ {
            key-positions = <POS_LH_C1R2 POS_LH_C1R1>;
            bindings = <&kp F5>;
            layers = <LAYER_HRM_macOS LAYER_HRM_WinLinx LAYER_Typing LAYER_Autoshift>;
        };

        // F6 combo for Go60 - TailorKey
        combo_F6_cb_v1_TKZ {
            key-positions = <POS_RH_C1R1 POS_RH_C1R2>;
            bindings = <&kp F6>;
            layers = <LAYER_HRM_macOS LAYER_HRM_WinLinx LAYER_Typing LAYER_Autoshift>;
        };

        // F7 combo for Go60 - TailorKey
        combo_F7_cb_v1_TKZ {
            key-positions = <POS_RH_C2R1 POS_RH_C2R2>;
            bindings = <&kp F7>;
            layers = <LAYER_HRM_macOS LAYER_HRM_WinLinx LAYER_Typing LAYER_Autoshift>;
        };

        // F8 combo for Go60 - TailorKey
        combo_F8_cb_v1_TKZ {
            key-positions = <POS_RH_C3R1 POS_RH_C3R2>;
            bindings = <&kp F8>;
            layers = <LAYER_HRM_macOS LAYER_HRM_WinLinx LAYER_Typing LAYER_Autoshift>;
        };

        // F9 combo for Go60 - TailorKey
        combo_F9_cb_v1_TKZ {
            key-positions = <POS_RH_C4R1 POS_RH_C4R2>;
            bindings = <&kp F9>;
            layers = <LAYER_HRM_macOS LAYER_HRM_WinLinx LAYER_Typing LAYER_Autoshift>;
        };

        // sticky "hyper" modifiers (Win + Alt + Ctrl + Shift) - Use with Tab - TailorKey
        combo_sticky_hyp_rght_v1_TKZ {
            timeout-ms = <50>;
            key-positions = <POS_RH_C2R5 POS_RH_C2R4>;
            bindings = <&sk LG(LA(LC(LSHFT)))>;
            layers = <LAYER_HRM_macOS LAYER_Autoshift LAYER_HRM_WinLinx>;
        };

        // sticky "meh" modifiers (Alt + Ctrl + Shift) - Use with Tab - TailorKey
        combo_sticky_meh_rght_v1_TKZ {
            timeout-ms = <50>;
            key-positions = <POS_RH_C3R5 POS_RH_C3R4>;
            bindings = <&sk LA(LC(LSHFT))>;
            layers = <LAYER_HRM_macOS LAYER_Autoshift LAYER_HRM_WinLinx>;
        };

        // Alt Tab Switcher (Cursor Layer) - TailorKey
        combo_tabswitch_alt_v1_TKZ {
            key-positions = <POS_LH_C4R4 POS_LH_C4R5>;
            bindings = <&mod_tab_chord_v2_TKZ LALT LAYER_Cursor>;
            layers = <LAYER_HRM_macOS LAYER_Typing LAYER_Autoshift LAYER_HRM_WinLinx>;
        };

        // Alt Tab Switcher (Cursor Layer) - TailorKey
        combo_tabswitch_ctrl_v1_TKZ {
            key-positions = <POS_LH_C2R4 POS_LH_C2R5>;
            bindings = <&mod_tab_chord_v2_TKZ LCTRL LAYER_Cursor>;
            layers = <LAYER_HRM_macOS LAYER_Typing LAYER_Autoshift LAYER_HRM_WinLinx>;
        };

        // Alt Tab Switcher (Cursor Layer) - TailorKey
        combo_tabswitch_gui_v1_TKZ {
            key-positions = <POS_LH_T1 POS_LH_C1R4>;
            bindings = <&mod_tab_chord_v2_TKZ LGUI LAYER_Cursor>;
            layers = <LAYER_HRM_macOS LAYER_Typing LAYER_Autoshift LAYER_HRM_WinLinx>;
        };

        // toggle gaming layer - TailorKey
        combo_gaming_layer_v1_TKZ {
            timeout-ms = <50>;
            key-positions = <POS_LH_C1R4 POS_LH_C2R5>;
            bindings = <&tog LAYER_Gaming>;
        };
    };
};

/* Automatically generated keymap */
/ {
    keymap {
        compatible = "zmk,keymap";


        layer_HRM_macOS {
            bindings = <
            &kp EQUAL                          &kp N1                        &kp N2                         &kp N3                          &kp N4                           &kp N5                                                                                                                                                                                                                          &kp N6                           &kp N7                          &kp N8                         &kp N9                              &kp N0         &kp MINUS
              &kp TAB                           &kp Q                         &kp W                          &kp E                           &kp R                            &kp T                                                                                                                                                                                                                           &kp Y                            &kp U                           &kp I                          &kp O                               &kp P          &kp BSLH
              &kp ESC  &HRM_left_pinky_v1_TKZ LCTRL A  &HRM_left_ring_v1_TKZ LALT S  &HRM_left_middy_v1_TKZ LGUI D  &HRM_left_index_v1_TKZ LSHFT F  &WM_hold_v1 LAYER_WM_practice G                                                                                                                                                                                               &WM_hold_H_v1 LAYER_WM_practice H  &HRM_right_index_v1_TKZ RSHFT J  &HRM_right_middy_v1_TKZ RGUI K  &HRM_right_ring_v1_TKZ LALT L  &HRM_right_pinky_v1_TKZ RCTRL SEMI           &kp SQT
 &magic LAYER_Magic 0                           &kp Z                         &kp X                          &kp C                           &kp V                            &kp B                                                                                                                                                                                                                           &kp N                            &kp M                       &kp COMMA                        &kp DOT                            &kp FSLH  &td_LAYER_Keypad
                                                                           &kp HOME                       &kp LEFT                       &kp RIGHT                                                                                                                                                                                                                                                                                            &kp UP                        &kp DOWN                        &kp END
                                                                                                                                                                                     &thumb_v2_TKZ LAYER_Cursor_macOS BSPC  &thumb_v2_TKZ LAYER_Keypad DEL  &kp LSHFT  &kp RALT  &thumb_v2_TKZ LAYER_Mouse RET  &space_v3_TKZ LAYER_Symbol SPACE
            >;
        };

        layer_HRM_WinLinx {
            bindings = <
            &kp EQUAL                         &kp N1                        &kp N2                          &kp N3                          &kp N4                      &kp N5                                                                                                                                                                                                             &kp N6                           &kp N7                           &kp N8                         &kp N9                             &kp N0         &kp MINUS
              &kp TAB                          &kp Q                         &kp W                           &kp E                           &kp R                       &kp T                                                                                                                                                                                                              &kp Y                            &kp U                            &kp I                          &kp O                              &kp P          &kp BSLH
              &kp ESC  &HRM_left_pinky_v1_TKZ LGUI A  &HRM_left_ring_v1_TKZ LALT S  &HRM_left_middy_v1_TKZ LCTRL D  &HRM_left_index_v1_TKZ LSHFT F  &WM_hold_v1 LAYER_WM_Win G                                                                                                                                                                                       &WM_hold_H_v1 LAYER_WM_Win H  &HRM_right_index_v1_TKZ RSHFT J  &HRM_right_middy_v1_TKZ RCTRL K  &HRM_right_ring_v1_TKZ LALT L  &HRM_right_pinky_v1_TKZ RGUI SEMI           &kp SQT
 &magic LAYER_Magic 0                          &kp Z                         &kp X                           &kp C                           &kp V                       &kp B                                                                                                                                                                                                              &kp N                            &kp M                        &kp COMMA                        &kp DOT                           &kp FSLH  &td_LAYER_Keypad
                                                                          &kp HOME                        &kp LEFT                       &kp RIGHT                                                                                                                                                                                                                                                                          &kp UP                         &kp DOWN  &thumb_v2_TKZ LAYER_Teams END
                                                                                                                                                                                &thumb_v2_TKZ LAYER_Cursor BSPC  &thumb_v2_TKZ LAYER_Keypad DEL  &kp LSHFT  &kp RALT  &thumb_v2_TKZ LAYER_Mouse RET  &space_v3_TKZ LAYER_Symbol SPACE
            >;
        };

        layer_Typing {
            bindings = <
               &trans  &trans  &trans  &trans  &trans  &trans                                                  &trans  &trans  &trans  &trans    &trans  &trans
               &trans  &trans  &trans  &trans  &trans  &trans                                                  &trans  &trans  &trans  &trans    &trans  &trans
               &trans   &kp A   &kp S   &kp D   &kp F   &kp G                                                   &kp H   &kp J   &kp K   &kp L  &kp SEMI  &trans
 &magic LAYER_Magic 0  &trans  &trans  &trans  &trans  &trans                                                  &trans  &trans  &trans  &trans    &trans  &trans
                               &trans  &trans  &trans                                                                  &trans  &trans  &trans
                                                               &trans  &trans  &trans  &trans  &trans  &trans
            >;
        };

        layer_Autoshift {
            bindings = <
     &AS_v1_TKZ EQUAL  &AS_v1_TKZ N1  &AS_v1_TKZ N2  &AS_v1_TKZ N3  &AS_v1_TKZ N4  &AS_v1_TKZ N5                                                  &AS_v1_TKZ N6  &AS_v1_TKZ N7     &AS_v1_TKZ N8    &AS_v1_TKZ N9    &AS_v1_TKZ N0  &AS_v1_TKZ MINUS
               &trans   &AS_v1_TKZ Q   &AS_v1_TKZ W   &AS_v1_TKZ E   &AS_v1_TKZ R   &AS_v1_TKZ T                                                   &AS_v1_TKZ Y   &AS_v1_TKZ U      &AS_v1_TKZ I     &AS_v1_TKZ O     &AS_v1_TKZ P   &AS_v1_TKZ BSLH
               &trans   &AS_v1_TKZ A   &AS_v1_TKZ S   &AS_v1_TKZ D   &AS_v1_TKZ F   &AS_v1_TKZ G                                                   &AS_v1_TKZ H   &AS_v1_TKZ J      &AS_v1_TKZ K     &AS_v1_TKZ L  &AS_v1_TKZ SEMI    &AS_v1_TKZ SQT
 &magic LAYER_Magic 0   &AS_v1_TKZ Z   &AS_v1_TKZ X   &AS_v1_TKZ C   &AS_v1_TKZ V   &AS_v1_TKZ B                                                   &AS_v1_TKZ N   &AS_v1_TKZ M  &AS_v1_TKZ COMMA   &AS_v1_TKZ DOT  &AS_v1_TKZ FSLH            &trans
                                             &trans         &trans         &trans                                                                                       &trans            &trans  &AS_v1_TKZ LBKT
                                                                                                  &trans  &trans  &trans  &trans  &trans  &trans
            >;
        };

        layer_Cursor {
            bindings = <
     &none    &kp ESC                  &kp INS              &kp LS(TAB)    &kp DEL      &none                                                                                                                           &none        &none      &kp K_APP  &kp PAUSE_BREAK   &kp SLCK      &none
  &kp CAPS    &kp RET                &kp LC(Y)                &kp LC(Z)   &kp BSPC  &kp LC(X)                                                                                                                       &kp LC(X)  &kp LS(TAB)      &kp LC(Z)        &kp LC(Y)    &kp TAB  &kp PSCRN
 &sk LSHFT   &kp LGUI                 &kp LALT                &kp LCTRL  &kp LSHFT  &kp LC(C)                                                                                                                       &kp LC(C)     &kp LEFT         &kp UP         &kp DOWN  &kp RIGHT  &sk RSHFT
 &kp LC(L)  &kp LC(A)  &cur_SELECT_LINE_v1_TKZ  &cur_SELECT_WORD_v1_TKZ  &kp LC(F)  &kp LC(V)                                                                                                                       &kp LC(V)     &kp HOME      &kp PG_UP        &kp PG_DN    &kp END  &kp LC(L)
                                         &none            &kp LC(LS(G))  &kp LC(G)                                                                                                                                               &kp LC(F)  &kp LC(LS(G))        &kp LC(G)
                                                                                                &none  &mod_tab_v2_TKZ LCTRL  &kp LG(D)  &cur_SELECT_NONE_v1_TKZ  &cur_EXTEND_LINE_v1_TKZ  &cur_EXTEND_WORD_v1_TKZ
            >;
        };

        layer_Cursor_macOS {
            bindings = <
     &none    &kp ESC                        &kp INS                    &kp LS(TAB)    &kp DEL      &none                                                                                                                                       &none        &none      &kp K_APP  &kp PAUSE_BREAK   &kp SLCK      &none
  &kp CAPS    &kp RET                  &kp LS(LG(Z))                      &kp LG(Z)   &kp BSPC  &kp LG(X)                                                                                                                                   &kp LG(X)  &kp LS(TAB)      &kp LG(Z)    &kp LS(LG(Z))    &kp TAB  &kp PSCRN
 &sk LSHFT  &kp LCTRL                       &kp LALT                       &kp LGUI  &kp LSHFT  &kp LG(C)                                                                                                                                   &kp LG(C)     &kp LEFT         &kp UP         &kp DOWN  &kp RIGHT  &sk RSHFT
 &kp LG(L)  &kp LG(A)  &cur_SELECT_LINE_macos_v1_TKZ  &cur_SELECT_WORD_macos_v1_TKZ  &kp LG(F)  &kp LG(V)                                                                                                                                   &kp LG(V)     &kp HOME      &kp PG_UP        &kp PG_DN    &kp END  &kp LG(L)
                                               &none                  &kp LS(LG(G))  &kp LG(G)                                                                                                                                                           &kp LG(F)  &kp LS(LG(G))        &kp LG(G)
                                                                                                            &none  &mod_tab_v2_TKZ LGUI  &kp LG(F3)  &cur_SELECT_NONE_v1_TKZ  &cur_EXTEND_LINE_macos_v1_TKZ  &cur_EXTEND_WORD_macos_v1_TKZ
            >;
        };

        layer_Symbol {
            bindings = <
     &kp GRAVE      &kp COMMA    &kp LS(N9)            &kp LS(N0)       &kp SEMI       &kp DOT                                                                               &none      &none        &none                &none      &none   &none
    &kp LS(N1)       &kp LBKT  &kp LS(LBKT)          &kp LS(RBKT)       &kp RBKT  &kp LS(FSLH)                                                                           &kp GRAVE    &kp DEL  &kp LS(TAB)              &kp INS    &kp ESC   &none
    &kp LS(N3)     &kp LS(N6)     &kp EQUAL         &kp LS(MINUS)     &kp LS(N4)    &kp LS(N8)                                                                &kp LS(SINGLE_QUOTE)   &kp BSPC      &kp TAB            &kp SPACE    &kp RET   &none
 &kp LS(GRAVE)  &kp LS(COMMA)  &kp LS(BSLH)             &kp MINUS    &kp LS(DOT)      &kp FSLH                                                                             &kp SQT  &sk LSHFT     &sk LGUI             &sk LALT  &sk LCTRL   &none
                                    &kp SQT  &kp LS(SINGLE_QUOTE)  &kp LS(EQUAL)                                                                                                     &kp BSLH   &kp LS(N7)  &symb_dotdot_v1_TKZ
                                                                                                &kp LS(N5)  &kp LS(SEMI)  &kp LS(N2)   &none   &none   &none
            >;
        };

        layer_Gaming {
            bindings = <
   &kp ESC     &kp N1    &kp N2  &kp N3  &kp N4  &kp N5                                                                &kp N6    &kp N7    &kp N8         &kp N9       &kp N0      &kp MINUS
   &kp RET    &kp TAB     &kp Q   &kp W   &kp E   &kp R                                                                 &kp Y     &kp U     &kp I          &kp O        &kp P  &kp LS(EQUAL)
 &kp GRAVE  &kp LSHFT     &kp A   &kp S   &kp D   &kp F                                                                 &kp H     &kp J     &kp K          &kp L     &kp SEMI    &kp LS(SQT)
     &kp B  &kp LCTRL     &kp Z   &kp X   &kp C   &kp V                                                                 &kp N     &kp M    &kp UP  &kp LS(COMMA)  &kp LS(DOT)       &kp LGUI
                       &kp LALT   &kp T   &kp G                                                                                &kp LEFT  &kp DOWN      &kp RIGHT
                                                         &kp SPACE  &kp LSHFT  &kp LCTRL  &kp BSPC  &kp LALT  &kp RET
            >;
        };

        layer_Keypad {
            bindings = <
                &none         &kp F1     &kp F2     &kp F3     &kp F4         &kp F5                                                        &kp F6     &kp F7      &kp F8        &kp F9          &kp F10              &kp F11
              &kp TAB          &none   &kp HOME     &kp UP    &kp END      &kp PG_UP                                                     &kp KP_N7  &kp KP_N8   &kp KP_N9  &kp KP_MINUS     &kp KP_SLASH              &kp F12
              &kp ESC  &kp LG(LS(Y))   &kp LEFT   &kp DOWN  &kp RIGHT      &kp PG_DN                                                     &kp KP_N4  &kp KP_N5   &kp KP_N6   &kp KP_PLUS  &kp KP_MULTIPLY           &kp KP_NUM
 &magic LAYER_Magic 0      &kp LG(Z)  &kp LG(X)  &kp LG(C)  &kp LG(V)  &kp LS(LG(V))                                                     &kp KP_N1  &kp KP_N2   &kp KP_N3  &kp KP_ENTER        &kp EQUAL  &to LAYER_HRM_macOS
                                          &none     &trans     &trans                                                                               &kp KP_N0  &kp KP_DOT  &kp KP_ENTER
                                                                                       &none  &trans  &trans  &trans  &trans  &kp KP_N0
            >;
        };

        layer_Mouse {
            bindings = <
  &none           &none                &none                &none                &none           &none                                                                                   &none                &none                &none                &none      &none     &none
  &none           &none       &msc SCRL_LEFT         &mmv MOVE_UP      &msc SCRL_RIGHT           &none                                                                                   &none            &sk RSHFT            &sk RCTRL             &sk RALT   &sk RGUI     &none
  &none    &msc SCRL_UP       &mmv MOVE_LEFT       &mmv MOVE_DOWN      &mmv MOVE_RIGHT    &msc SCRL_UP                                                                            &msc SCRL_UP  &mo LAYER_MouseFast  &mo LAYER_MouseWarp  &mo LAYER_MouseSlow  &mkp LCLK  &mkp MB4
  &none  &msc SCRL_DOWN  &mo LAYER_MouseSlow  &mo LAYER_MouseWarp  &mo LAYER_MouseFast  &msc SCRL_DOWN                                                                          &msc SCRL_DOWN       &msc SCRL_LEFT         &mmv MOVE_UP      &msc SCRL_RIGHT  &mkp RCLK  &mkp MB5
                                   &kp LG(X)            &kp LG(C)            &kp LG(V)                                                                                                               &mmv MOVE_LEFT       &mmv MOVE_DOWN      &mmv MOVE_RIGHT
                                                                                                        &mkp LCLK  &mkp RCLK  &mkp MB4  &mkp LCLK  &tog LAYER_Mouse  &mkp RCLK
            >;
        };

        layer_MouseSlow {
            bindings = <
 &trans  &trans  &trans  &trans  &trans  &trans                                                  &trans  &trans  &trans  &trans  &trans  &trans
 &trans  &trans  &trans  &trans  &trans  &trans                                                  &trans  &trans  &trans  &trans  &trans  &trans
 &trans  &trans  &trans  &trans  &trans  &trans                                                  &trans  &trans  &trans  &trans  &trans  &trans
 &trans  &trans  &trans  &trans  &trans  &trans                                                  &trans  &trans  &trans  &trans  &trans  &trans
                 &trans  &trans  &trans                                                                  &trans  &trans  &trans
                                                 &trans  &trans  &trans  &trans  &trans  &trans
            >;
        };

        layer_MouseFast {
            bindings = <
 &trans  &trans  &trans  &trans  &trans  &trans                                                  &trans  &trans  &trans  &trans  &trans  &trans
 &trans  &trans  &trans  &trans  &trans  &trans                                                  &trans  &trans  &trans  &trans  &trans  &trans
 &trans  &trans  &trans  &trans  &trans  &trans                                                  &trans  &trans  &trans  &trans  &trans  &trans
 &trans  &trans  &trans  &trans  &trans  &trans                                                  &trans  &trans  &trans  &trans  &trans  &trans
                 &trans  &trans  &trans                                                                  &trans  &trans  &trans
                                                 &trans  &trans  &trans  &trans  &trans  &trans
            >;
        };

        layer_MouseWarp {
            bindings = <
 &trans  &trans  &trans  &trans  &trans  &trans                                                  &trans  &trans  &trans  &trans  &trans  &trans
 &trans  &trans  &trans  &trans  &trans  &trans                                                  &trans  &trans  &trans  &trans  &trans  &trans
 &trans  &trans  &trans  &trans  &trans  &trans                                                  &trans  &trans  &trans  &trans  &trans  &trans
 &trans  &trans  &trans  &trans  &trans  &trans                                                  &trans  &trans  &trans  &trans  &trans  &trans
                 &trans  &trans  &trans                                                                  &trans  &trans  &trans
                                                 &trans  &trans  &trans  &trans  &trans  &trans
            >;
        };

        layer_Magic {
            bindings = <
 &mstr1_v1_TKZ     &kp C_BRI_DN     &kp C_BRI_UP       &kp C_PREV        &kp C_NEXT         &kp C_PP                                                                                                      &kp C_MUTE      &kp C_VOL_DN  &kp C_VOL_UP   &none  &bt BT_CLR  &bt BT_CLR_ALL
   &bootloader  &rgb_ug RGB_SPI  &rgb_ug RGB_SAI  &rgb_ug RGB_HUI   &rgb_ug RGB_BRI  &rgb_ug RGB_TOG                                                                                                           &none             &none         &none   &none       &none     &bootloader
    &sys_reset  &rgb_ug RGB_SPD  &rgb_ug RGB_SAD  &rgb_ug RGB_HUD   &rgb_ug RGB_BRD  &rgb_ug RGB_EFF                                                                                           &to LAYER_WM_practice  &to LAYER_WM_Win         &none   &none       &none      &sys_reset
         &none            &none        &bt_hop_0        &bt_hop_1         &bt_hop_2        &bt_hop_3                                                                                                           &to LAYER_VSCode_macOS  &to LAYER_VSCode_Win         &none   &none       &none           &none
                                    &out OUT_USB            &none  &to LAYER_Typing                                                                                                                                              &none         &none   &none
                                                                                                      &to LAYER_HRM_WinLinx  &to LAYER_HRM_macOS  &to LAYER_Autoshift   &none   &none   &none
            >;
        };

        layer_WM_practice {
            bindings = <
 &to LAYER_HRM_macOS       &trans       &trans       &trans       &trans  &trans                                                                  &trans       &trans       &trans       &trans       &trans       &trans
         &kp LS(F15)  &kp LS(F13)  &kp LA(F19)  &kp LA(F20)  &kp LS(F14)  &trans                                                                  &trans  &kp LC(F13)  &kp LC(F14)  &kp LC(F15)  &kp LC(F16)  &kp LA(F13)
              &trans      &kp F13      &kp F14      &kp F15      &kp F16  &trans                                                                   &trans      &kp F17      &kp F18      &kp F19      &kp F20  &kp LA(F14)
              &trans       &trans       &trans       &trans       &trans  &trans                                                                  &trans  &kp LC(F17)  &kp LC(F18)  &kp LC(F19)  &kp LC(F20)  &kp LA(F15)
                                        &trans       &trans       &trans                                                                                  &kp LA(F16)  &kp LA(F17)  &kp LA(F18)
                                                                                  &trans  &trans  &tog LAYER_WM_practice  &trans  &trans  &trans
            >;
        };

        layer_WM_Win {
            bindings = <
 &to LAYER_HRM_WinLinx      &kp F21      &kp F22      &kp F23      &kp F24  &kp LC(F21)                                                             &kp LC(F22)   &kp LA(F21)  &kp LA(F22)   &kp LA(F23)    &kp LA(F24)  &kp LC(F23)
           &kp LS(F15)  &kp LS(F13)  &kp LA(F19)  &kp LA(F20)  &kp LS(F14)       &trans                                                                  &trans   &kp LC(F13)  &kp LC(F14)   &kp LC(F15)    &kp LC(F16)  &kp LA(F13)
                &trans      &kp F13      &kp F14      &kp F15      &kp F16       &trans                                                                  &trans       &kp F17      &kp F18       &kp F19        &kp F20  &kp LA(F14)
                &trans  &kp LC(F24)  &kp LS(F23)  &kp LS(F24)       &trans       &trans                                                                  &trans   &kp LC(F17)  &kp LC(F18)   &kp LC(F19)    &kp LC(F20)  &kp LA(F15)
                                          &trans       &trans       &trans                                                                                        &kp LA(F16)  &kp LA(F17)   &kp LA(F18)
                                                                                         &trans  &trans  &tog LAYER_WM_Win  &trans  &trans  &trans
            >;
        };

        layer_VSCode_macOS {
            bindings = <
          &trans           &trans           &trans           &trans         &trans             &trans                                                           &trans            &trans            &trans           &trans     &trans  &trans
    &kp LG(BSLH)          &kp LA(K)           &trans           &trans  &kp LG(LS(T))      &kp LC(GRAVE)                                                           &trans  &kp LG(LS(LBKT))  &kp LG(LS(RBKT))      &kp LC(TAB)     &trans  &trans
 &kp LA(LS(F17))  &kp LA(LS(F13))  &kp LA(LS(F15))  &kp LA(LS(F14))  &kp LA(LS(F16))  &kp LC(LS(GRAVE))                                                    &kp LC(R)  &kp LC(LS(F13))  &kp LC(LS(F15))  &kp LC(LS(F14))  &kp LC(LS(F16))  &trans
          &trans           &trans           &trans  &kp LG(LS(ESC))     &kp LG(ESC)        &kp LS(F19)                                                           &trans            &trans            &trans           &trans     &trans  &trans
                                            &trans           &trans         &trans                                                                                                &trans            &trans           &trans
                                                                                                       &trans  &trans  &trans  &trans  &trans  &trans
            >;
        };

        layer_VSCode_Win {
            bindings = <
          &trans           &trans           &trans           &trans         &trans             &trans                                                           &trans           &trans           &trans           &trans     &trans  &trans
    &kp LC(BSLH)          &kp LA(K)           &trans           &trans  &kp LC(LS(T))      &kp LC(GRAVE)                                                           &trans    &kp LC(PG_UP)    &kp LC(PG_DN)      &kp LC(TAB)     &trans  &trans
 &kp LA(LS(F17))  &kp LA(LS(F13))  &kp LA(LS(F15))  &kp LA(LS(F14))  &kp LA(LS(F16))  &kp LC(LS(GRAVE))                                                  &kp LC(R)  &kp LC(LS(F13))  &kp LC(LS(F15))  &kp LC(LS(F14))  &kp LC(LS(F16))  &trans
          &trans           &trans           &trans      &kp LS(F18)      &kp LS(F17)        &kp LS(F19)                                                           &trans           &trans           &trans           &trans     &trans  &trans
                                            &trans           &trans         &trans                                                                                               &trans           &trans           &trans
                                                                                                       &trans  &trans  &trans  &trans  &trans  &trans
            >;
        };

        layer_Teams {
            bindings = <
 &trans  &trans         &trans      &trans         &trans     &trans                                                     &trans          &trans      &trans     &trans  &trans  &trans
 &trans  &trans         &trans   &kp LC(E)  &kp LA(LS(R))  &kp LC(R)                                                     &trans   &kp LC(LA(U))      &trans     &trans  &trans  &trans
 &trans  &trans         &trans      &trans      &kp LC(F)  &kp LC(G)                                                     &trans  &kp LC(LS(F6))  &kp LC(F6)  &kp LC(L)  &trans  &trans
 &trans  &trans  &kp LC(LS(X))  &kp LC(N2)  &kp LC(LA(R))     &trans                                                  &kp LC(N)       &kp LC(M)      &trans     &trans  &trans  &trans
                        &trans      &trans         &trans                                                                                &trans      &trans     &trans
                                                                      &trans  &trans  &trans  &trans  &trans  &trans
            >;
        };

        // Windows overlay for Keypad (8). Redo is `LC(Y)`, matching what
        // layer_Cursor already uses for redo on this OS; the macOS side of
        // this position is still `LG(LS(Y))`, which is redo on neither OS.
        layer_Keypad_Win {
            bindings = <
 &trans  &trans  &trans  &trans  &trans  &trans                                                       &trans  &trans  &trans  &trans  &trans  &trans
 &trans  &trans  &trans  &trans  &trans  &trans                                                       &trans  &trans  &trans  &trans  &trans  &trans
 &trans  &kp LC(Y)  &trans  &trans  &trans  &trans                                                       &trans  &trans  &trans  &trans  &trans  &trans
 &trans  &kp LC(Z)  &kp LC(X)  &kp LC(C)  &kp LC(V)  &kp LC(LS(V))                                                       &trans  &trans  &trans  &trans  &trans  &trans
                 &trans  &trans  &trans                                                                       &trans  &trans  &trans
                                       &trans  &trans  &trans  &trans  &trans  &trans
            >;
        };

        // Windows overlay for Mouse (9) — cut/copy/paste under the resting
        // left hand. Also covers the pointer-triggered activation, which a
        // twin layer could not.
        layer_Mouse_Win {
            bindings = <
 &trans  &trans  &trans  &trans  &trans  &trans                                                       &trans  &trans  &trans  &trans  &trans  &trans
 &trans  &trans  &trans  &trans  &trans  &trans                                                       &trans  &trans  &trans  &trans  &trans  &trans
 &trans  &trans  &trans  &trans  &trans  &trans                                                       &trans  &trans  &trans  &trans  &trans  &trans
 &trans  &trans  &trans  &trans  &trans  &trans                                                       &trans  &trans  &trans  &trans  &trans  &trans
                 &kp LC(X)  &kp LC(C)  &kp LC(V)                                                                       &trans  &trans  &trans
                                       &trans  &trans  &trans  &trans  &trans  &trans
            >;
        };

    };
};
